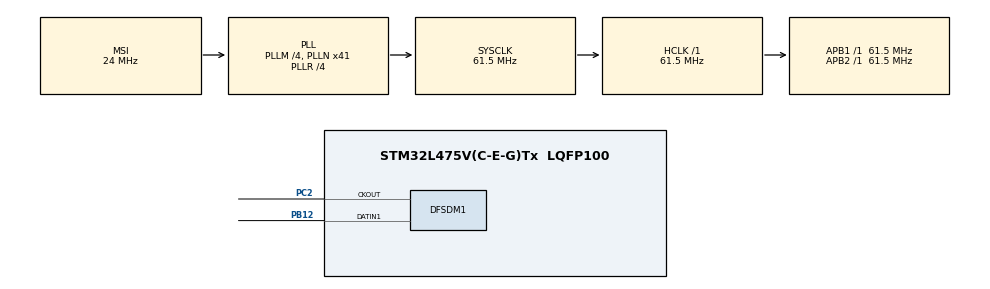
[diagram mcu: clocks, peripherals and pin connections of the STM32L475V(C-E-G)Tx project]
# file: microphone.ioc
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DFSDM1.Divider=60
DFSDM1.DmaMode_reg_FIL0=ENABLE
DFSDM1.DmaMode_reg_FIL1=ENABLE
DFSDM1.FastMode_reg_FIL0=ENABLE
DFSDM1.FastMode_reg_FIL1=ENABLE
DFSDM1.Filter_injChannel0_FIL0=__NULL
DFSDM1.Filter_regChannel_FIL0=DFSDM_CHANNEL_1
DFSDM1.Filter_regChannel_FIL1=DFSDM_CHANNEL_0
DFSDM1.Fosr_FIL0=64
DFSDM1.Fosr_FIL1=64
DFSDM1.RightBitShift_CH0=0x02
DFSDM1.RightBitShift_CH1=0x02
DFSDM1.Selection=DFSDM_CHANNEL_OUTPUT_CLOCK_AUDIO
DFSDM1.SincOrder_FIL0=DFSDM_FILTER_SINC4_ORDER
DFSDM1.SincOrder_FIL1=DFSDM_FILTER_SINC4_ORDER
DFSDM1.Type_spi_CH0=DFSDM_CHANNEL_SPI_FALLING
Dma.DFSDM1_FLT0.0.Direction=DMA_PERIPH_TO_MEMORY
Dma.DFSDM1_FLT0.0.Instance=DMA1_Channel4
Dma.DFSDM1_FLT0.0.MemDataAlignment=DMA_MDATAALIGN_WORD
Dma.DFSDM1_FLT0.0.MemInc=DMA_MINC_ENABLE
Dma.DFSDM1_FLT0.0.Mode=DMA_CIRCULAR
Dma.DFSDM1_FLT0.0.PeriphDataAlignment=DMA_PDATAALIGN_WORD
Dma.DFSDM1_FLT0.0.PeriphInc=DMA_PINC_DISABLE
Dma.DFSDM1_FLT0.0.Priority=DMA_PRIORITY_LOW
Dma.DFSDM1_FLT1.1.Direction=DMA_PERIPH_TO_MEMORY
Dma.DFSDM1_FLT1.1.Instance=DMA1_Channel5
Dma.DFSDM1_FLT1.1.MemDataAlignment=DMA_MDATAALIGN_WORD
Dma.DFSDM1_FLT1.1.MemInc=DMA_MINC_ENABLE
Dma.DFSDM1_FLT1.1.Mode=DMA_CIRCULAR
Dma.DFSDM1_FLT1.1.PeriphDataAlignment=DMA_PDATAALIGN_WORD
Dma.DFSDM1_FLT1.1.PeriphInc=DMA_PINC_DISABLE
Dma.DFSDM1_FLT1.1.Priority=DMA_PRIORITY_LOW
Dma.Request0=DFSDM1_FLT0
Dma.Request1=DFSDM1_FLT1
FREERTOS.Mutexes01=buffer_mutex,Dynamic,NULL
FREERTOS.Tasks01=defaultTask,24,128,StartDefaultTask,Default,NULL,Dynamic,NULL,NULL;tasktest_out,24,128,test_out,Default,NULL,Dynamic,NULL,NULL
FREERTOS.configUSE_NEWLIB_REENTRANT=1
Mcu.Family=STM32L4
Mcu.Name=STM32L475V(C-E-G)Tx
Mcu.Package=LQFP100
NVIC.DMA1_Channel4_IRQn=true\:5\:0\:false\:false\:true\:true\:false\:true
NVIC.DMA1_Channel5_IRQn=true\:5\:0\:false\:false\:true\:true\:false\:true
NVIC.PriorityGroup=NVIC_PRIORITYGROUP_4
NVIC.TIM1_UP_TIM16_IRQn=true\:15\:0\:false\:false\:true\:false\:false\:true
NVIC.TimeBase=TIM1_UP_TIM16_IRQn
NVIC.TimeBaseIP=TIM1
PA13\ (JTMS-SWDIO).Mode=Serial_Wire
PA13\ (JTMS-SWDIO).Signal=SYS_JTMS-SWDIO
PA14\ (JTCK-SWCLK).Mode=Serial_Wire
PA14\ (JTCK-SWCLK).Signal=SYS_JTCK-SWCLK
PB12.Signal=S_DATAIN1DFSDM1
PC2.Signal=S_CKOUTDFSDM1
ProjectManager.HeapSize=0x200
ProjectManager.StackSize=0x400
ProjectManager.TargetToolchain=STM32CubeIDE
RCC.ADCFreq_Value=33000000
RCC.AHBFreq_Value=61500000
RCC.APB1Freq_Value=61500000
RCC.APB1TimFreq_Value=61500000
RCC.APB2Freq_Value=61500000
RCC.APB2TimFreq_Value=61500000
RCC.CortexFreq_Value=61500000
RCC.HCLKFreq_Value=61500000
RCC.HSE_VALUE=8000000
RCC.HSI_VALUE=16000000
RCC.LSE_VALUE=32768
RCC.MSIClockRange=RCC_MSIRANGE_9
RCC.MSI_VALUE=24000000
RCC.PLLM=4
RCC.PLLN=41
RCC.PLLR=RCC_PLLR_DIV4
RCC.PLLSAI1N=11
RCC.SYSCLKFreq_VALUE=61500000
RCC.SYSCLKSource=RCC_SYSCLKSOURCE_PLLCLK
RCC.USBFreq_Value=33000000
RCC.VCOOutputFreq_Value=246000000
SH.S_CKOUTDFSDM1.0=DFSDM1_CKOUT,PDM_SPI_input_from_ch1_and_internal_clock
SH.S_CKOUTDFSDM1.1=DFSDM1_CKOUT,PDM_SPI_Input_from_ch01_and_Internal_Clock
SH.S_DATAIN1DFSDM1.0=DFSDM1_DATIN1,PDM_SPI_input_from_ch1_and_internal_clock
SH.S_DATAIN1DFSDM1.1=DFSDM1_DATIN1,PDM_SPI_Input_from_ch01_and_Internal_Clock
VP_FREERTOS_VS_CMSIS_V2.Mode=CMSIS_V2
VP_SYS_VS_tim1.Mode=TIM1
board=B-L475E-IOT01A2

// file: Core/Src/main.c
/* USER CODE BEGIN Header */
/**
  ******************************************************************************
  * @file           : main.c
  * @brief          : Main program body
  ******************************************************************************
  * @attention
  *
  * Copyright (c) 2021 STMicroelectronics.
  * All rights reserved.
  *
  * This software is licensed under terms that can be found in the LICENSE file
  * in the root directory of this software component.
  * If no LICENSE file comes with this software, it is provided AS-IS.
  *
  ******************************************************************************
  */
/* USER CODE END Header */
#include "main.h"
#include "cmsis_os.h"
#include "dfsdm.h"
#include "dma.h"
#include "gpio.h"

/* USER CODE BEGIN Includes */
#include "stm32l475e_iot01_audio.h"
#include "microphone.h"
#include <stdlib.h>
#include <stdio.h>
/* USER CODE END Includes */

void SystemClock_Config(void);
void MX_FREERTOS_Init(void);

/* USER CODE BEGIN 0 */

static BSP_AUDIO_Init_t MicParams;

static int16_t *BUFFER_RIS;

int mic_init(){

	BUFFER_RIS = (int16_t*)calloc(AUDIO_SAMPLING_FREQUENCY * 2, sizeof(int16_t));

    if (!BUFFER_RIS) {
            printf("Failed to allocate BUFFER_RIS buffer\n");
            return -1;
        }

    init_buffer(BUFFER_RIS);

    // set up the microphone
    MicParams.BitsPerSample = 16;
    MicParams.ChannelsNbr = AUDIO_CHANNELS;
    MicParams.Device = AUDIO_IN_DIGITAL_MIC1;
    MicParams.SampleRate = AUDIO_SAMPLING_FREQUENCY;
    MicParams.Volume = 32;

    int32_t ret = BSP_AUDIO_IN_Init(AUDIO_INSTANCE, &MicParams);

    if (ret != BSP_ERROR_NONE) {
        printf("Error Audio Init (%ld)\r\n", ret);
        return -1;
    } else {
        printf("OK Audio Init\t(Audio Freq=%d)\r\n", AUDIO_SAMPLING_FREQUENCY);
    }

    return 0;

}

/* USER CODE END 0 */

int main(void)
{

  /* MCU Configuration--------------------------------------------------------*/

  /* Reset of all peripherals, Initializes the Flash interface and the Systick. */
  HAL_Init();

  /* Configure the system clock */
  SystemClock_Config();

  /* Initialize all configured peripherals */
  MX_GPIO_Init();
  MX_DMA_Init();
  //MX_DFSDM1_Init(); USING INIT FROM EXTERNAL LIBRARY
  /* USER CODE BEGIN 2 */
  if(mic_init() == -1){
      printf("Something goes wrong");
      return -1;
    };

  //xTaskCreate(taskTakeMic, "taskMic", 115, NULL, 0, NULL);
  //printf("task create\n");
  /* USER CODE END 2 */

  /* Init scheduler */
  osKernelInitialize();  /* Call init function for freertos objects (in freertos.c) */
  MX_FREERTOS_Init();
  /* Start scheduler */
  osKernelStart();

  /* We should never get here as control is now taken by the scheduler */
  /* Infinite loop */
  while (1)
  {

  }
}

void SystemClock_Config(void)
{
  RCC_OscInitTypeDef RCC_OscInitStruct = {0};
  RCC_ClkInitTypeDef RCC_ClkInitStruct = {0};

  /** Configure the main internal regulator output voltage
  */
  if (HAL_PWREx_ControlVoltageScaling(PWR_REGULATOR_VOLTAGE_SCALE1) != HAL_OK)
  {
    Error_Handler();
  }
  /** Initializes the RCC Oscillators according to the specified parameters
  * in the RCC_OscInitTypeDef structure.
  */
  RCC_OscInitStruct.OscillatorType = RCC_OSCILLATORTYPE_MSI;
  RCC_OscInitStruct.MSIState = RCC_MSI_ON;
  RCC_OscInitStruct.MSICalibrationValue = 0;
  RCC_OscInitStruct.MSIClockRange = RCC_MSIRANGE_9;
  RCC_OscInitStruct.PLL.PLLState = RCC_PLL_ON;
  RCC_OscInitStruct.PLL.PLLSource = RCC_PLLSOURCE_MSI;
  RCC_OscInitStruct.PLL.PLLM = 4;
  RCC_OscInitStruct.PLL.PLLN = 41;
  RCC_OscInitStruct.PLL.PLLP = RCC_PLLP_DIV7;
  RCC_OscInitStruct.PLL.PLLQ = RCC_PLLQ_DIV2;
  RCC_OscInitStruct.PLL.PLLR = RCC_PLLR_DIV4;
  if (HAL_RCC_OscConfig(&RCC_OscInitStruct) != HAL_OK)
  {
    Error_Handler();
  }
  /** Initializes the CPU, AHB and APB buses clocks
  */
  RCC_ClkInitStruct.ClockType = RCC_CLOCKTYPE_HCLK|RCC_CLOCKTYPE_SYSCLK
                              |RCC_CLOCKTYPE_PCLK1|RCC_CLOCKTYPE_PCLK2;
  RCC_ClkInitStruct.SYSCLKSource = RCC_SYSCLKSOURCE_PLLCLK;
  RCC_ClkInitStruct.AHBCLKDivider = RCC_SYSCLK_DIV1;
  RCC_ClkInitStruct.APB1CLKDivider = RCC_HCLK_DIV1;
  RCC_ClkInitStruct.APB2CLKDivider = RCC_HCLK_DIV1;

  if (HAL_RCC_ClockConfig(&RCC_ClkInitStruct, FLASH_LATENCY_3) != HAL_OK)
  {
    Error_Handler();
  }
}

void HAL_TIM_PeriodElapsedCallback(TIM_HandleTypeDef *htim)
{
  if (htim->Instance == TIM1) {
    HAL_IncTick();
  }
}

void Error_Handler(void)
{
  __disable_irq();
  while (1)
  {
  }
}

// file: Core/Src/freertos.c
/* USER CODE BEGIN Header */
/**
  ******************************************************************************
  * File Name          : freertos.c
  * Description        : Code for freertos applications
  ******************************************************************************
  * @attention
  *
  * Copyright (c) 2021 STMicroelectronics.
  * All rights reserved.
  *
  * This software is licensed under terms that can be found in the LICENSE file
  * in the root directory of this software component.
  * If no LICENSE file comes with this software, it is provided AS-IS.
  *
  ******************************************************************************
  */
/* USER CODE END Header */

#include "FreeRTOS.h"
#include "task.h"
#include "main.h"
#include "cmsis_os.h"

/* USER CODE BEGIN Includes */
#include "microphone.h"
/* USER CODE END Includes */

/* Definitions for defaultTask */
osThreadId_t defaultTaskHandle;
const osThreadAttr_t defaultTask_attributes = {
  .name = "defaultTask",
  .stack_size = 128 * 4,
  .priority = (osPriority_t) osPriorityNormal,
};
/* Definitions for tasktest_out */
osThreadId_t tasktest_outHandle;
const osThreadAttr_t tasktest_out_attributes = {
  .name = "tasktest_out",
  .stack_size = 128 * 4,
  .priority = (osPriority_t) osPriorityNormal,
};
/* Definitions for buffer_mutex */
osMutexId_t buffer_mutexHandle;
const osMutexAttr_t buffer_mutex_attributes = {
  .name = "buffer_mutex"
};

/* USER CODE BEGIN FunctionPrototypes */
osThreadId_t tasktest_mic;
void taskTakeMic(void *pvParameters);
/* USER CODE END FunctionPrototypes */

void StartDefaultTask(void *argument);
void test_out(void *argument);

void MX_FREERTOS_Init(void); /* (MISRA C 2004 rule 8.1) */

void MX_FREERTOS_Init(void) {
  /* Create the mutex(es) */
  /* creation of buffer_mutex */
  buffer_mutexHandle = osMutexNew(&buffer_mutex_attributes);

  /* Create the thread(s) */
  /* creation of defaultTask */
  defaultTaskHandle = osThreadNew(StartDefaultTask, NULL, &defaultTask_attributes);

  /* creation of tasktest_out */
  tasktest_outHandle = osThreadNew(test_out, NULL, &tasktest_out_attributes);

  tasktest_mic = osThreadNew(taskTakeMic, NULL, &tasktest_out_attributes);

}

void StartDefaultTask(void *argument)
{
  for(;;)
  {
    osDelay(1);
  }
}

void test_out(void *argument)
{
  for(;;)
  {
    osDelay(1);
  }
}

/* USER CODE BEGIN Application */
void taskTakeMic(void *pvParameters){
	while(1){
		start_recording();
		printf("restart\n");
	}
}

/* USER CODE END Application */
